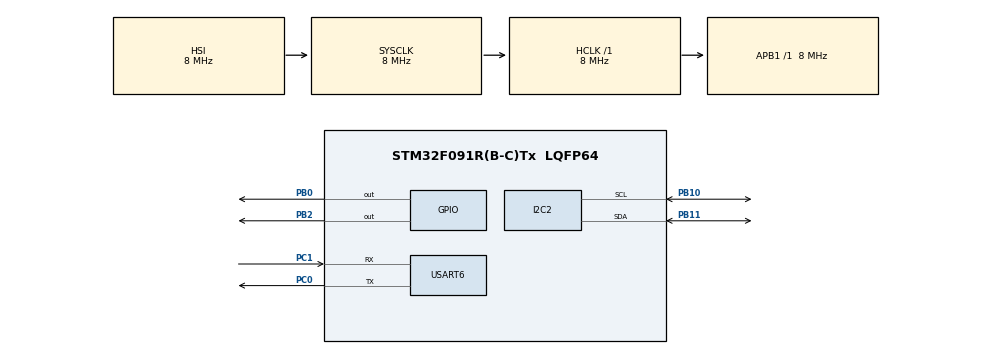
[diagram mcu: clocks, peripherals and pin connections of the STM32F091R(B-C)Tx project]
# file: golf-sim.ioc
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Mcu.Family=STM32F0
Mcu.Name=STM32F091R(B-C)Tx
Mcu.Package=LQFP64
NVIC.USART3_8_IRQn=true\:0\:0\:false\:false\:true\:true\:true\:true
PB0.GPIO_ModeDefaultOutputPP=GPIO_MODE_OUTPUT_PP
PB0.GPIO_PuPd=GPIO_PULLUP
PB0.Signal=GPIO_Output
PB10.GPIO_Mode=GPIO_MODE_AF_OD
PB10.GPIO_Pu=GPIO_PULLUP
PB10.GPIO_Speed=GPIO_SPEED_FREQ_HIGH
PB10.Mode=I2C
PB10.Signal=I2C2_SCL
PB11.GPIO_Mode=GPIO_MODE_AF_OD
PB11.GPIO_Pu=GPIO_PULLUP
PB11.Mode=I2C
PB11.Signal=I2C2_SDA
PB2.GPIO_PuPd=GPIO_PULLUP
PB2.PinState=GPIO_PIN_SET
PB2.Signal=GPIO_Output
PC0.Mode=Asynchronous
PC0.Signal=USART6_TX
PC1.Mode=Asynchronous
PC1.Signal=USART6_RX
ProjectManager.HeapSize=0x200
ProjectManager.StackSize=0x400
ProjectManager.TargetToolchain=STM32CubeIDE
RCC.AHBFreq_Value=8000000
RCC.APB1Freq_Value=8000000
RCC.APB1TimFreq_Value=8000000
RCC.HCLKFreq_Value=8000000
RCC.SYSCLKFreq_VALUE=8000000
USART6.VirtualMode=VM_ASYNC
board=custom

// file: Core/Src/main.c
/* USER CODE BEGIN Header */
/**
  ******************************************************************************
  * @file           : main.c
  * @brief          : Main program body
  ******************************************************************************
  * @attention
  *
  * Copyright (c) 2023 STMicroelectronics.
  * All rights reserved.
  *
  * This software is licensed under terms that can be found in the LICENSE file
  * in the root directory of this software component.
  * If no LICENSE file comes with this software, it is provided AS-IS.
  *
  ******************************************************************************
  */
/* USER CODE END Header */
#include "main.h"
#include "imu.h"

I2C_HandleTypeDef hi2c2;

UART_HandleTypeDef huart6;

void SystemClock_Config(void);
static void MX_GPIO_Init(void);
static void MX_I2C2_Init(void);
static void MX_USART6_UART_Init(void);

/* USER CODE BEGIN 0 */

uint8_t Rx_data[10];
/* USER CODE END 0 */

int main(void)
{

  /* MCU Configuration--------------------------------------------------------*/

  /* Reset of all peripherals, Initializes the Flash interface and the Systick. */
  HAL_Init();

  /* Configure the system clock */
  SystemClock_Config();

  /* Initialize all configured peripherals */
  MX_GPIO_Init();
  GPIOB->ODR |= GPIO_ODR_2;
  MX_I2C2_Init();
  MX_USART6_UART_Init();
  //IMU_Init();

  HAL_UART_Receive_IT(&huart6, Rx_data, 10);

  /* Infinite loop */
  while (1)
  {
	  __HAL_UART_CLEAR_PEFLAG(&huart6);
	  __HAL_UART_CLEAR_FEFLAG(&huart6);
	  __HAL_UART_CLEAR_NEFLAG(&huart6);
	  __HAL_UART_CLEAR_OREFLAG(&huart6);
	  __HAL_UART_CLEAR_FLAG(&huart6, UART_CLEAR_CTSF);
	  HAL_UART_Receive_IT(&huart6, Rx_data, 10);

  }
}

void SystemClock_Config(void)
{
  RCC_OscInitTypeDef RCC_OscInitStruct = {0};
  RCC_ClkInitTypeDef RCC_ClkInitStruct = {0};

  /** Initializes the RCC Oscillators according to the specified parameters
  * in the RCC_OscInitTypeDef structure.
  */
  RCC_OscInitStruct.OscillatorType = RCC_OSCILLATORTYPE_HSI;
  RCC_OscInitStruct.HSIState = RCC_HSI_ON;
  RCC_OscInitStruct.HSICalibrationValue = RCC_HSICALIBRATION_DEFAULT;
  RCC_OscInitStruct.PLL.PLLState = RCC_PLL_NONE;
  if (HAL_RCC_OscConfig(&RCC_OscInitStruct) != HAL_OK)
  {
    Error_Handler();
  }

  /** Initializes the CPU, AHB and APB buses clocks
  */
  RCC_ClkInitStruct.ClockType = RCC_CLOCKTYPE_HCLK|RCC_CLOCKTYPE_SYSCLK
                              |RCC_CLOCKTYPE_PCLK1;
  RCC_ClkInitStruct.SYSCLKSource = RCC_SYSCLKSOURCE_HSI;
  RCC_ClkInitStruct.AHBCLKDivider = RCC_SYSCLK_DIV1;
  RCC_ClkInitStruct.APB1CLKDivider = RCC_HCLK_DIV1;

  if (HAL_RCC_ClockConfig(&RCC_ClkInitStruct, FLASH_LATENCY_0) != HAL_OK)
  {
    Error_Handler();
  }
}

static void MX_I2C2_Init(void)
{

  hi2c2.Instance = I2C2;
  hi2c2.Init.Timing = 0x2000090E;
  hi2c2.Init.OwnAddress1 = 214;
  hi2c2.Init.AddressingMode = I2C_ADDRESSINGMODE_7BIT;
  hi2c2.Init.DualAddressMode = I2C_DUALADDRESS_DISABLE;
  hi2c2.Init.OwnAddress2 = 0;
  hi2c2.Init.OwnAddress2Masks = I2C_OA2_NOMASK;
  hi2c2.Init.GeneralCallMode = I2C_GENERALCALL_DISABLE;
  hi2c2.Init.NoStretchMode = I2C_NOSTRETCH_DISABLE;
  if (HAL_I2C_Init(&hi2c2) != HAL_OK)
  {
    Error_Handler();
  }

  /** Configure Analogue filter
  */
  if (HAL_I2CEx_ConfigAnalogFilter(&hi2c2, I2C_ANALOGFILTER_ENABLE) != HAL_OK)
  {
    Error_Handler();
  }

  /** Configure Digital filter
  */
  if (HAL_I2CEx_ConfigDigitalFilter(&hi2c2, 0) != HAL_OK)
  {
    Error_Handler();
  }

}

static void MX_USART6_UART_Init(void)
{

  huart6.Instance = USART6;
  huart6.Init.BaudRate = 115200;
  huart6.Init.WordLength = UART_WORDLENGTH_8B;
  huart6.Init.StopBits = UART_STOPBITS_1;
  huart6.Init.Parity = UART_PARITY_NONE;
  huart6.Init.Mode = UART_MODE_TX_RX;
  huart6.Init.HwFlowCtl = UART_HWCONTROL_NONE;
  huart6.Init.OverSampling = UART_OVERSAMPLING_16;
  huart6.Init.OneBitSampling = UART_ONE_BIT_SAMPLE_DISABLE;
  huart6.AdvancedInit.AdvFeatureInit = UART_ADVFEATURE_NO_INIT;
  if (HAL_UART_Init(&huart6) != HAL_OK)
  {
    Error_Handler();
  }

}

static void MX_GPIO_Init(void)
{
  GPIO_InitTypeDef GPIO_InitStruct = {0};

  /* GPIO Ports Clock Enable */
  __HAL_RCC_GPIOC_CLK_ENABLE();
  __HAL_RCC_GPIOB_CLK_ENABLE();

  /*Configure GPIO pin Output Level */
  HAL_GPIO_WritePin(GPIOB, GPIO_PIN_0, GPIO_PIN_RESET);

  /*Configure GPIO pin Output Level */
  HAL_GPIO_WritePin(GPIOB, GPIO_PIN_2, GPIO_PIN_SET);

  /*Configure GPIO pins : PB0 PB2 */
  GPIO_InitStruct.Pin = GPIO_PIN_0|GPIO_PIN_2;
  GPIO_InitStruct.Mode = GPIO_MODE_OUTPUT_PP;
  GPIO_InitStruct.Pull = GPIO_PULLUP;
  GPIO_InitStruct.Speed = GPIO_SPEED_FREQ_LOW;
  HAL_GPIO_Init(GPIOB, &GPIO_InitStruct);

}

/* USER CODE BEGIN 4 */
void HAL_UART_RxCpltCallback(UART_HandleTypeDef *huart) {
//	HAL_StatusTypeDef received;
//	__HAL_UART_CLEAR_PEFLAG(&huart6);
//	__HAL_UART_CLEAR_FEFLAG(&huart6);
//	__HAL_UART_CLEAR_NEFLAG(&huart6);
//	__HAL_UART_CLEAR_OREFLAG(&huart6);
//	__HAL_UART_CLEAR_FLAG(&huart6, UART_CLEAR_CTSF);
//	received = HAL_UART_Receive_IT(&huart6, Rx_data, 10);

	if (Rx_data[5] == 'i') {

		HAL_UART_Transmit(&huart6, "ack1", 4, HAL_MAX_DELAY);
		for(int i = 0; i < 100000; i++) {

		}
		HAL_UART_Transmit(&huart6, "ack1", 4, HAL_MAX_DELAY);
		for(int i = 0; i < 100000; i++) {

		}
		IMU_Init();

	} else if (Rx_data[5] == 'c'){
//		HAL_UART_Transmit(&huart6, "ack2", 4, HAL_MAX_DELAY);

		//GPIOB->ODR &= ~GPIO_ODR_2;
	}
}

//void HAL_I2C_MasterRXCpltCallback (I2C_HandleTypeDef * hi2c) {
//	// receiving done, do something ...
//	READ_DATA();
//}
/* USER CODE END 4 */

void Error_Handler(void)
{
  __disable_irq();
  while (1)
  {
  }
}
